# MSS_CTRL_MSS_CTRL_50D00000h register map
Vendor: Texas Instruments
Registers are 32-bit, read-write, reset values left out (the file's numbers can be read two ways) unless marked. A register's access mark holds for its fields unless they carry their own. Offsets are as the file gives them; [hi:lo] are bit positions; {n}, {i} and the like mark numbered series.

## MSS_CTRL (part 3 of 4)
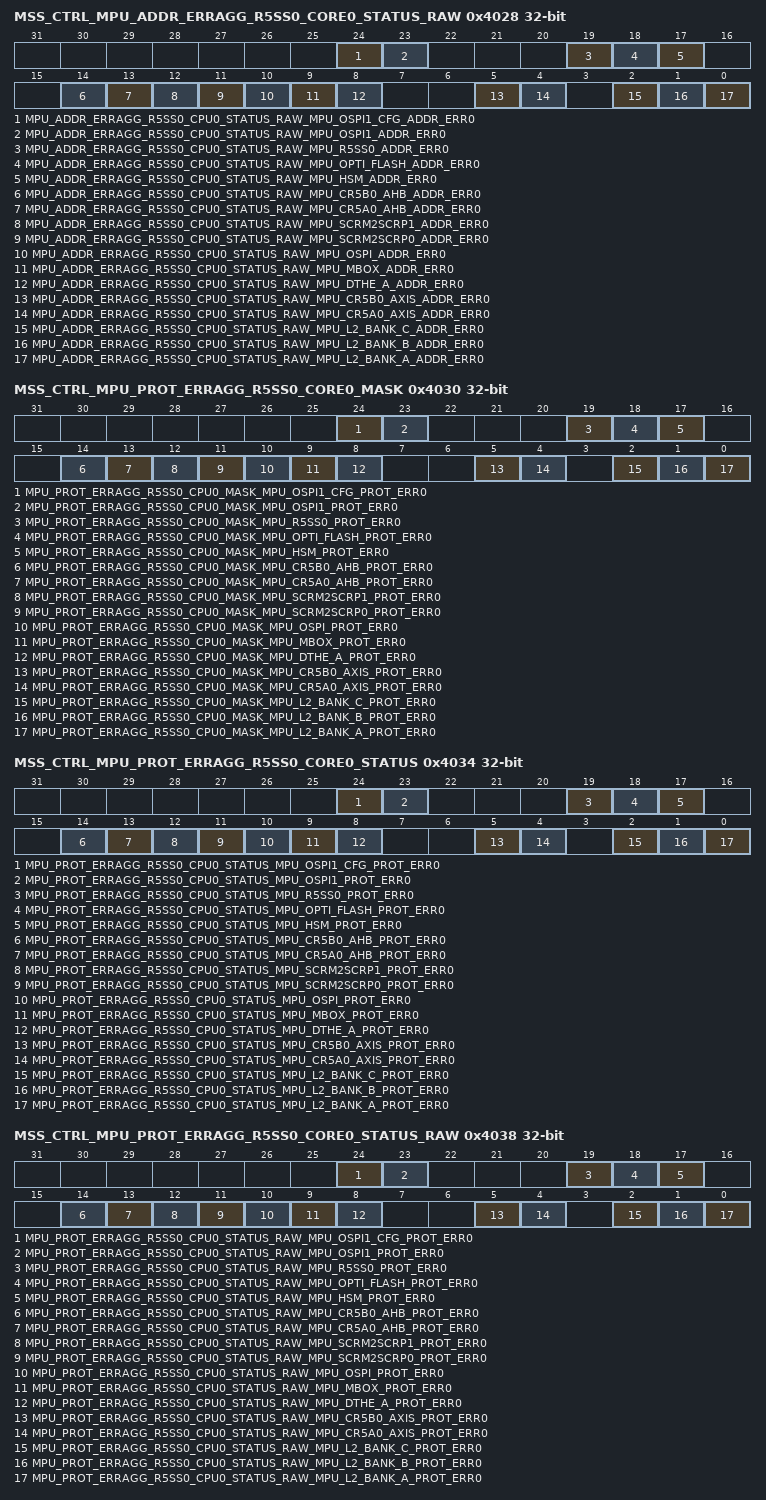
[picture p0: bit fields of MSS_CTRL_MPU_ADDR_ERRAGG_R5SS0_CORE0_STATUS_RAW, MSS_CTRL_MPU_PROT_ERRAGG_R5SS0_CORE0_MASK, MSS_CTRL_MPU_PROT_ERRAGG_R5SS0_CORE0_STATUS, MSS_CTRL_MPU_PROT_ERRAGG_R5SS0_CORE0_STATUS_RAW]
0x4028 MSS_CTRL_MPU_ADDR_ERRAGG_R5SS0_CORE0_STATUS_RAW access not given — This register shows the Status of all MPU Address Errors.
  [24] MPU_ADDR_ERRAGG_R5SS0_CPU0_STATUS_RAW_MPU_OSPI1_CFG_ADDR_ERR0 — Raw Status of Error from MPU_ADDR_INTR. Set irrespective if the Interupt is masked or unmasked in MPU_ADDR_INTR_ERRAGG_MASK (access R/W1TC)
  [23] MPU_ADDR_ERRAGG_R5SS0_CPU0_STATUS_RAW_MPU_OSPI1_ADDR_ERR0 — Raw Status of Error from MPU_ADDR_INTR. Set irrespective if the Interupt is masked or unmasked in MPU_ADDR_INTR_ERRAGG_MASK (access R/W1TC)
  [19] MPU_ADDR_ERRAGG_R5SS0_CPU0_STATUS_RAW_MPU_R5SS0_ADDR_ERR0 — Raw Status of Error from MPU_ADDR_INTR. Set irrespective if the Interupt is masked or unmasked in MPU_ADDR_INTR_ERRAGG_MASK (access R/W1TC)
  [18] MPU_ADDR_ERRAGG_R5SS0_CPU0_STATUS_RAW_MPU_OPTI_FLASH_ADDR_ERR0 — Raw Status of Error from MPU_ADDR_INTR. Set irrespective if the Interupt is masked or unmasked in MPU_ADDR_INTR_ERRAGG_MASK (access R/W1TC)
  [17] MPU_ADDR_ERRAGG_R5SS0_CPU0_STATUS_RAW_MPU_HSM_ADDR_ERR0 — Raw Status of Error from MPU_ADDR_INTR. Set irrespective if the Interupt is masked or unmasked in MPU_ADDR_INTR_ERRAGG_MASK (access R/W1TC)
  [14] MPU_ADDR_ERRAGG_R5SS0_CPU0_STATUS_RAW_MPU_CR5B0_AHB_ADDR_ERR0 — Raw Status of Error from MPU_ADDR_INTR. Set irrespective if the Interupt is masked or unmasked in MPU_ADDR_INTR_ERRAGG_MASK (access R/W1TC)
  [13] MPU_ADDR_ERRAGG_R5SS0_CPU0_STATUS_RAW_MPU_CR5A0_AHB_ADDR_ERR0 — Raw Status of Error from MPU_ADDR_INTR. Set irrespective if the Interupt is masked or unmasked in MPU_ADDR_INTR_ERRAGG_MASK (access R/W1TC)
  [12] MPU_ADDR_ERRAGG_R5SS0_CPU0_STATUS_RAW_MPU_SCRM2SCRP1_ADDR_ERR0 — Raw Status of Error from MPU_ADDR_INTR. Set irrespective if the Interupt is masked or unmasked in MPU_ADDR_INTR_ERRAGG_MASK (access R/W1TC)
  [11] MPU_ADDR_ERRAGG_R5SS0_CPU0_STATUS_RAW_MPU_SCRM2SCRP0_ADDR_ERR0 — Raw Status of Error from MPU_ADDR_INTR. Set irrespective if the Interupt is masked or unmasked in MPU_ADDR_INTR_ERRAGG_MASK (access R/W1TC)
  [10] MPU_ADDR_ERRAGG_R5SS0_CPU0_STATUS_RAW_MPU_OSPI_ADDR_ERR0 — Raw Status of Error from MPU_ADDR_INTR. Set irrespective if the Interupt is masked or unmasked in MPU_ADDR_INTR_ERRAGG_MASK (access R/W1TC)
  [9] MPU_ADDR_ERRAGG_R5SS0_CPU0_STATUS_RAW_MPU_MBOX_ADDR_ERR0 — Raw Status of Error from MPU_ADDR_INTR. Set irrespective if the Interupt is masked or unmasked in MPU_ADDR_INTR_ERRAGG_MASK (access R/W1TC)
  [8] MPU_ADDR_ERRAGG_R5SS0_CPU0_STATUS_RAW_MPU_DTHE_A_ADDR_ERR0 — Raw Status of Error from MPU_ADDR_INTR. Set irrespective if the Interupt is masked or unmasked in MPU_ADDR_INTR_ERRAGG_MASK (access R/W1TC)
  [5] MPU_ADDR_ERRAGG_R5SS0_CPU0_STATUS_RAW_MPU_CR5B0_AXIS_ADDR_ERR0 — Raw Status of Error from MPU_ADDR_INTR. Set irrespective if the Interupt is masked or unmasked in MPU_ADDR_INTR_ERRAGG_MASK (access R/W1TC)
  [4] MPU_ADDR_ERRAGG_R5SS0_CPU0_STATUS_RAW_MPU_CR5A0_AXIS_ADDR_ERR0 — Raw Status of Error from MPU_ADDR_INTR. Set irrespective if the Interupt is masked or unmasked in MPU_ADDR_INTR_ERRAGG_MASK (access R/W1TC)
  [2] MPU_ADDR_ERRAGG_R5SS0_CPU0_STATUS_RAW_MPU_L2_BANK_C_ADDR_ERR0 — Raw Status of Error from MPU_ADDR_INTR. Set irrespective if the Interupt is masked or unmasked in MPU_ADDR_INTR_ERRAGG_MASK (access R/W1TC)
  [1] MPU_ADDR_ERRAGG_R5SS0_CPU0_STATUS_RAW_MPU_L2_BANK_B_ADDR_ERR0 — Raw Status of Error from MPU_ADDR_INTR. Set irrespective if the Interupt is masked or unmasked in MPU_ADDR_INTR_ERRAGG_MASK (access R/W1TC)
  [0] MPU_ADDR_ERRAGG_R5SS0_CPU0_STATUS_RAW_MPU_L2_BANK_A_ADDR_ERR0 — Raw Status of Error from MPU_ADDR_INTR. Set irrespective if the Interupt is masked or unmasked in MPU_ADDR_INTR_ERRAGG_MASK (access R/W1TC)
0x4030 MSS_CTRL_MPU_PROT_ERRAGG_R5SS0_CORE0_MASK — This register Masks selected interrupt soures from generating MPU Protection Error Interrupt to R5SS0 CORE0 .
  [24] MPU_PROT_ERRAGG_R5SS0_CPU0_MASK_MPU_OSPI1_CFG_PROT_ERR0 — Mask Error from MPU_PROT_INTR to aggregated Error MPU_PROT_INTR_ERRAGG1 : Error is Masked0 : Error is Unmasked
  [23] MPU_PROT_ERRAGG_R5SS0_CPU0_MASK_MPU_OSPI1_PROT_ERR0 — Mask Error from MPU_PROT_INTR to aggregated Error MPU_PROT_INTR_ERRAGG1 : Error is Masked0 : Error is Unmasked
  [19] MPU_PROT_ERRAGG_R5SS0_CPU0_MASK_MPU_R5SS0_PROT_ERR0 — Mask Error from MPU_PROT_INTR to aggregated Error MPU_PROT_INTR_ERRAGG1 : Error is Masked0 : Error is Unmasked
  [18] MPU_PROT_ERRAGG_R5SS0_CPU0_MASK_MPU_OPTI_FLASH_PROT_ERR0 — Mask Error from MPU_PROT_INTR to aggregated Error MPU_PROT_INTR_ERRAGG1 : Error is Masked0 : Error is Unmasked
  [17] MPU_PROT_ERRAGG_R5SS0_CPU0_MASK_MPU_HSM_PROT_ERR0 — Mask Error from MPU_PROT_INTR to aggregated Error MPU_PROT_INTR_ERRAGG1 : Error is Masked0 : Error is Unmasked
  [14] MPU_PROT_ERRAGG_R5SS0_CPU0_MASK_MPU_CR5B0_AHB_PROT_ERR0 — Mask Error from MPU_PROT_INTR to aggregated Error MPU_PROT_INTR_ERRAGG1 : Error is Masked0 : Error is Unmasked
  [13] MPU_PROT_ERRAGG_R5SS0_CPU0_MASK_MPU_CR5A0_AHB_PROT_ERR0 — Mask Error from MPU_PROT_INTR to aggregated Error MPU_PROT_INTR_ERRAGG1 : Error is Masked0 : Error is Unmasked
  [12] MPU_PROT_ERRAGG_R5SS0_CPU0_MASK_MPU_SCRM2SCRP1_PROT_ERR0 — Mask Error from MPU_PROT_INTR to aggregated Error MPU_PROT_INTR_ERRAGG1 : Error is Masked0 : Error is Unmasked
  [11] MPU_PROT_ERRAGG_R5SS0_CPU0_MASK_MPU_SCRM2SCRP0_PROT_ERR0 — Mask Error from MPU_PROT_INTR to aggregated Error MPU_PROT_INTR_ERRAGG1 : Error is Masked0 : Error is Unmasked
  [10] MPU_PROT_ERRAGG_R5SS0_CPU0_MASK_MPU_OSPI_PROT_ERR0 — Mask Error from MPU_PROT_INTR to aggregated Error MPU_PROT_INTR_ERRAGG1 : Error is Masked0 : Error is Unmasked
  [9] MPU_PROT_ERRAGG_R5SS0_CPU0_MASK_MPU_MBOX_PROT_ERR0 — Mask Error from MPU_PROT_INTR to aggregated Error MPU_PROT_INTR_ERRAGG1 : Error is Masked0 : Error is Unmasked
  [8] MPU_PROT_ERRAGG_R5SS0_CPU0_MASK_MPU_DTHE_A_PROT_ERR0 — Mask Error from MPU_PROT_INTR to aggregated Error MPU_PROT_INTR_ERRAGG1 : Error is Masked0 : Error is Unmasked
  [5] MPU_PROT_ERRAGG_R5SS0_CPU0_MASK_MPU_CR5B0_AXIS_PROT_ERR0 — Mask Error from MPU_PROT_INTR to aggregated Error MPU_PROT_INTR_ERRAGG1 : Error is Masked0 : Error is Unmasked
  [4] MPU_PROT_ERRAGG_R5SS0_CPU0_MASK_MPU_CR5A0_AXIS_PROT_ERR0 — Mask Error from MPU_PROT_INTR to aggregated Error MPU_PROT_INTR_ERRAGG1 : Error is Masked0 : Error is Unmasked
  [2] MPU_PROT_ERRAGG_R5SS0_CPU0_MASK_MPU_L2_BANK_C_PROT_ERR0 — Mask Error from MPU_PROT_INTR to aggregated Error MPU_PROT_INTR_ERRAGG1 : Error is Masked0 : Error is Unmasked
  [1] MPU_PROT_ERRAGG_R5SS0_CPU0_MASK_MPU_L2_BANK_B_PROT_ERR0 — Mask Error from MPU_PROT_INTR to aggregated Error MPU_PROT_INTR_ERRAGG1 : Error is Masked0 : Error is Unmasked
  [0] MPU_PROT_ERRAGG_R5SS0_CPU0_MASK_MPU_L2_BANK_A_PROT_ERR0 — Mask Error from MPU_PROT_INTR to aggregated Error MPU_PROT_INTR_ERRAGG1 : Error is Masked0 : Error is Unmasked
0x4034 MSS_CTRL_MPU_PROT_ERRAGG_R5SS0_CORE0_STATUS access not given — This register shows the Status of Unmasked MPU Protection Errors to R5SS0 Core0 .
  [24] MPU_PROT_ERRAGG_R5SS0_CPU0_STATUS_MPU_OSPI1_CFG_PROT_ERR0 — Status of Error from MPU_PROT_INTR. Set only if Interupt is unmasked in MPU_PROT_INTR_ERRAGG_MASKWrie 0x1 to clear this Error. (access R/W1TC)
  [23] MPU_PROT_ERRAGG_R5SS0_CPU0_STATUS_MPU_OSPI1_PROT_ERR0 — Status of Error from MPU_PROT_INTR. Set only if Interupt is unmasked in MPU_PROT_INTR_ERRAGG_MASKWrie 0x1 to clear this Error. (access R/W1TC)
  [19] MPU_PROT_ERRAGG_R5SS0_CPU0_STATUS_MPU_R5SS0_PROT_ERR0 — Status of Error from MPU_PROT_INTR. Set only if Interupt is unmasked in MPU_PROT_INTR_ERRAGG_MASKWrie 0x1 to clear this Error. (access R/W1TC)
  [18] MPU_PROT_ERRAGG_R5SS0_CPU0_STATUS_MPU_OPTI_FLASH_PROT_ERR0 — Status of Error from MPU_PROT_INTR. Set only if Interupt is unmasked in MPU_PROT_INTR_ERRAGG_MASKWrie 0x1 to clear this Error. (access R/W1TC)
  [17] MPU_PROT_ERRAGG_R5SS0_CPU0_STATUS_MPU_HSM_PROT_ERR0 — Status of Error from MPU_PROT_INTR. Set only if Interupt is unmasked in MPU_PROT_INTR_ERRAGG_MASKWrie 0x1 to clear this Error. (access R/W1TC)
  [14] MPU_PROT_ERRAGG_R5SS0_CPU0_STATUS_MPU_CR5B0_AHB_PROT_ERR0 — Status of Error from MPU_PROT_INTR. Set only if Interupt is unmasked in MPU_PROT_INTR_ERRAGG_MASKWrie 0x1 to clear this Error. (access R/W1TC)
  [13] MPU_PROT_ERRAGG_R5SS0_CPU0_STATUS_MPU_CR5A0_AHB_PROT_ERR0 — Status of Error from MPU_PROT_INTR. Set only if Interupt is unmasked in MPU_PROT_INTR_ERRAGG_MASKWrie 0x1 to clear this Error. (access R/W1TC)
  [12] MPU_PROT_ERRAGG_R5SS0_CPU0_STATUS_MPU_SCRM2SCRP1_PROT_ERR0 — Status of Error from MPU_PROT_INTR. Set only if Interupt is unmasked in MPU_PROT_INTR_ERRAGG_MASKWrie 0x1 to clear this Error. (access R/W1TC)
  [11] MPU_PROT_ERRAGG_R5SS0_CPU0_STATUS_MPU_SCRM2SCRP0_PROT_ERR0 — Status of Error from MPU_PROT_INTR. Set only if Interupt is unmasked in MPU_PROT_INTR_ERRAGG_MASKWrie 0x1 to clear this Error. (access R/W1TC)
  [10] MPU_PROT_ERRAGG_R5SS0_CPU0_STATUS_MPU_OSPI_PROT_ERR0 — Status of Error from MPU_PROT_INTR. Set only if Interupt is unmasked in MPU_PROT_INTR_ERRAGG_MASKWrie 0x1 to clear this Error. (access R/W1TC)
  [9] MPU_PROT_ERRAGG_R5SS0_CPU0_STATUS_MPU_MBOX_PROT_ERR0 — Status of Error from MPU_PROT_INTR. Set only if Interupt is unmasked in MPU_PROT_INTR_ERRAGG_MASKWrie 0x1 to clear this Error. (access R/W1TC)
  [8] MPU_PROT_ERRAGG_R5SS0_CPU0_STATUS_MPU_DTHE_A_PROT_ERR0 — Status of Error from MPU_PROT_INTR. Set only if Interupt is unmasked in MPU_PROT_INTR_ERRAGG_MASKWrie 0x1 to clear this Error. (access R/W1TC)
  [5] MPU_PROT_ERRAGG_R5SS0_CPU0_STATUS_MPU_CR5B0_AXIS_PROT_ERR0 — Status of Error from MPU_PROT_INTR. Set only if Interupt is unmasked in MPU_PROT_INTR_ERRAGG_MASKWrie 0x1 to clear this Error. (access R/W1TC)
  [4] MPU_PROT_ERRAGG_R5SS0_CPU0_STATUS_MPU_CR5A0_AXIS_PROT_ERR0 — Status of Error from MPU_PROT_INTR. Set only if Interupt is unmasked in MPU_PROT_INTR_ERRAGG_MASKWrie 0x1 to clear this Error. (access R/W1TC)
  [2] MPU_PROT_ERRAGG_R5SS0_CPU0_STATUS_MPU_L2_BANK_C_PROT_ERR0 — Status of Error from MPU_PROT_INTR. Set only if Interupt is unmasked in MPU_PROT_INTR_ERRAGG_MASKWrie 0x1 to clear this Error. (access R/W1TC)
  [1] MPU_PROT_ERRAGG_R5SS0_CPU0_STATUS_MPU_L2_BANK_B_PROT_ERR0 — Status of Error from MPU_PROT_INTR. Set only if Interupt is unmasked in MPU_PROT_INTR_ERRAGG_MASKWrie 0x1 to clear this Error. (access R/W1TC)
  [0] MPU_PROT_ERRAGG_R5SS0_CPU0_STATUS_MPU_L2_BANK_A_PROT_ERR0 — Status of Error from MPU_PROT_INTR. Set only if Interupt is unmasked in MPU_PROT_INTR_ERRAGG_MASKWrie 0x1 to clear this Error. (access R/W1TC)
0x4038 MSS_CTRL_MPU_PROT_ERRAGG_R5SS0_CORE0_STATUS_RAW access not given — This register shows the Status of all MPU Protection Errors.
  [24] MPU_PROT_ERRAGG_R5SS0_CPU0_STATUS_RAW_MPU_OSPI1_CFG_PROT_ERR0 — Raw Status of Error from MPU_PROT_INTR. Set irrespective if the Interupt is masked or unmasked in MPU_PROT_INTR_ERRAGG_MASK (access R/W1TC)
  [23] MPU_PROT_ERRAGG_R5SS0_CPU0_STATUS_RAW_MPU_OSPI1_PROT_ERR0 — Raw Status of Error from MPU_PROT_INTR. Set irrespective if the Interupt is masked or unmasked in MPU_PROT_INTR_ERRAGG_MASK (access R/W1TC)
  [19] MPU_PROT_ERRAGG_R5SS0_CPU0_STATUS_RAW_MPU_R5SS0_PROT_ERR0 — Raw Status of Error from MPU_PROT_INTR. Set irrespective if the Interupt is masked or unmasked in MPU_PROT_INTR_ERRAGG_MASK (access R/W1TC)
  [18] MPU_PROT_ERRAGG_R5SS0_CPU0_STATUS_RAW_MPU_OPTI_FLASH_PROT_ERR0 — Raw Status of Error from MPU_PROT_INTR. Set irrespective if the Interupt is masked or unmasked in MPU_PROT_INTR_ERRAGG_MASK (access R/W1TC)
  [17] MPU_PROT_ERRAGG_R5SS0_CPU0_STATUS_RAW_MPU_HSM_PROT_ERR0 — Raw Status of Error from MPU_PROT_INTR. Set irrespective if the Interupt is masked or unmasked in MPU_PROT_INTR_ERRAGG_MASK (access R/W1TC)
  [14] MPU_PROT_ERRAGG_R5SS0_CPU0_STATUS_RAW_MPU_CR5B0_AHB_PROT_ERR0 — Raw Status of Error from MPU_PROT_INTR. Set irrespective if the Interupt is masked or unmasked in MPU_PROT_INTR_ERRAGG_MASK (access R/W1TC)
  [13] MPU_PROT_ERRAGG_R5SS0_CPU0_STATUS_RAW_MPU_CR5A0_AHB_PROT_ERR0 — Raw Status of Error from MPU_PROT_INTR. Set irrespective if the Interupt is masked or unmasked in MPU_PROT_INTR_ERRAGG_MASK (access R/W1TC)
  [12] MPU_PROT_ERRAGG_R5SS0_CPU0_STATUS_RAW_MPU_SCRM2SCRP1_PROT_ERR0 — Raw Status of Error from MPU_PROT_INTR. Set irrespective if the Interupt is masked or unmasked in MPU_PROT_INTR_ERRAGG_MASK (access R/W1TC)
  [11] MPU_PROT_ERRAGG_R5SS0_CPU0_STATUS_RAW_MPU_SCRM2SCRP0_PROT_ERR0 — Raw Status of Error from MPU_PROT_INTR. Set irrespective if the Interupt is masked or unmasked in MPU_PROT_INTR_ERRAGG_MASK (access R/W1TC)
  [10] MPU_PROT_ERRAGG_R5SS0_CPU0_STATUS_RAW_MPU_OSPI_PROT_ERR0 — Raw Status of Error from MPU_PROT_INTR. Set irrespective if the Interupt is masked or unmasked in MPU_PROT_INTR_ERRAGG_MASK (access R/W1TC)
  [9] MPU_PROT_ERRAGG_R5SS0_CPU0_STATUS_RAW_MPU_MBOX_PROT_ERR0 — Raw Status of Error from MPU_PROT_INTR. Set irrespective if the Interupt is masked or unmasked in MPU_PROT_INTR_ERRAGG_MASK (access R/W1TC)
  [8] MPU_PROT_ERRAGG_R5SS0_CPU0_STATUS_RAW_MPU_DTHE_A_PROT_ERR0 — Raw Status of Error from MPU_PROT_INTR. Set irrespective if the Interupt is masked or unmasked in MPU_PROT_INTR_ERRAGG_MASK (access R/W1TC)
  [5] MPU_PROT_ERRAGG_R5SS0_CPU0_STATUS_RAW_MPU_CR5B0_AXIS_PROT_ERR0 — Raw Status of Error from MPU_PROT_INTR. Set irrespective if the Interupt is masked or unmasked in MPU_PROT_INTR_ERRAGG_MASK (access R/W1TC)
  [4] MPU_PROT_ERRAGG_R5SS0_CPU0_STATUS_RAW_MPU_CR5A0_AXIS_PROT_ERR0 — Raw Status of Error from MPU_PROT_INTR. Set irrespective if the Interupt is masked or unmasked in MPU_PROT_INTR_ERRAGG_MASK (access R/W1TC)
  [2] MPU_PROT_ERRAGG_R5SS0_CPU0_STATUS_RAW_MPU_L2_BANK_C_PROT_ERR0 — Raw Status of Error from MPU_PROT_INTR. Set irrespective if the Interupt is masked or unmasked in MPU_PROT_INTR_ERRAGG_MASK (access R/W1TC)
  [1] MPU_PROT_ERRAGG_R5SS0_CPU0_STATUS_RAW_MPU_L2_BANK_B_PROT_ERR0 — Raw Status of Error from MPU_PROT_INTR. Set irrespective if the Interupt is masked or unmasked in MPU_PROT_INTR_ERRAGG_MASK (access R/W1TC)
  [0] MPU_PROT_ERRAGG_R5SS0_CPU0_STATUS_RAW_MPU_L2_BANK_A_PROT_ERR0 — Raw Status of Error from MPU_PROT_INTR. Set irrespective if the Interupt is masked or unmasked in MPU_PROT_INTR_ERRAGG_MASK (access R/W1TC)
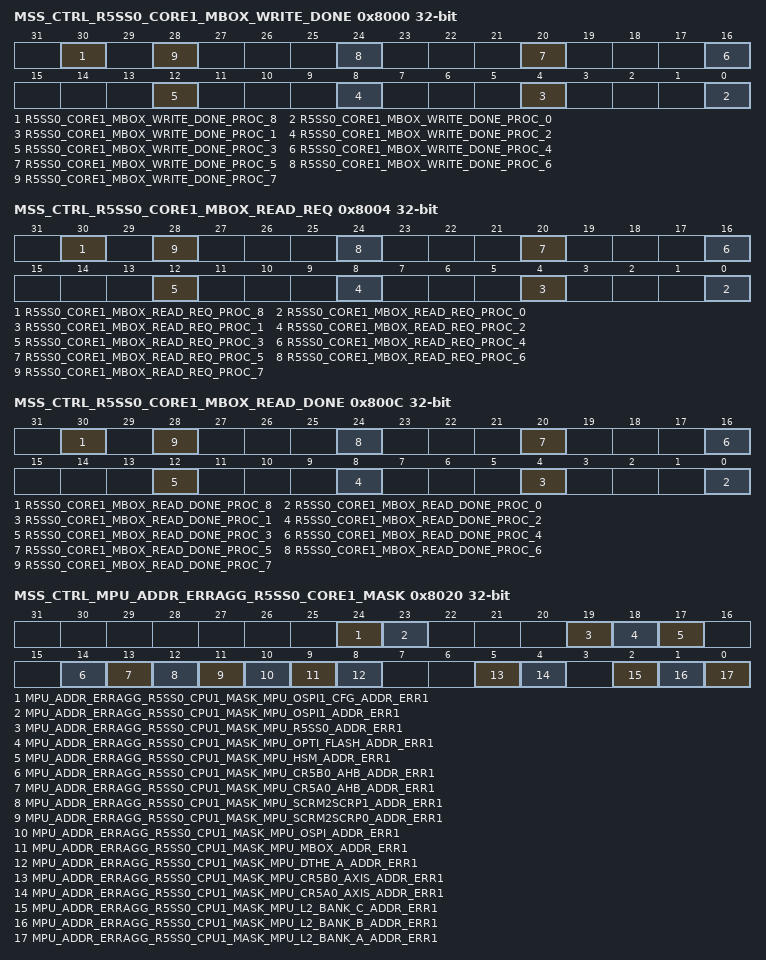
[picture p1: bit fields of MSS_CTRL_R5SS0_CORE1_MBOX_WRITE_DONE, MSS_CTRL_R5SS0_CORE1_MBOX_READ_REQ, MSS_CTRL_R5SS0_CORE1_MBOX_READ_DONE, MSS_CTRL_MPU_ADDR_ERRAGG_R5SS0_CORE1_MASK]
0x8000 MSS_CTRL_R5SS0_CORE1_MBOX_WRITE_DONE — This register is used by R5SS0 Core 1 to generate Mailbox interrupt to Recipent CPU.
  [30] R5SS0_CORE1_MBOX_WRITE_DONE_PROC_8 — Write pulse bit field:This register should be written once finishing Writing into the mailbox memory of processor 8
  [4n] R5SS0_CORE1_MBOX_WRITE_DONE_PROC_{n} (n=0..7) — Write pulse bit field:This register should be written once finishing Writing into the mailbox memory of processor {n}
0x8004 MSS_CTRL_R5SS0_CORE1_MBOX_READ_REQ access not given — This register is used by R5SS0 Core 1 to know the Sender of Mailbox Interrupt as well as clear it.
  [30] R5SS0_CORE1_MBOX_READ_REQ_PROC_8 — This is request from processor 8 to mss_CR5B. Requesting it to read from mailbox. (access R/W1TC)
  [4n] R5SS0_CORE1_MBOX_READ_REQ_PROC_{n} (n=0..7) — This is request from processor {n} to mss_CR5B. Requesting it to read from mailbox. (access R/W1TC)
0x8008 MSS_CTRL_R5SS0_CORE1_MBOX_READ_DONE_ACK — This register is used by R5SS0 Core 1 to generate Mailbox Read acknowledgement to the Sender CPU.
  [8:0] R5SS0_CORE1_MBOX_READ_DONE_ACK_PROC — Write pulse bit field:For bits 0 to7:Wrting1'b1 : Generates pulse interrupt to corresponding proc from MSS_CR5
0x800C MSS_CTRL_R5SS0_CORE1_MBOX_READ_DONE access not given — This register is used by R5SS0 Core 1 to know that the Receiver CPU has read the Mailbox and Acked. It is also used to clear the Read Done Interrupt.
  [30] R5SS0_CORE1_MBOX_READ_DONE_PROC_8 — This register should be written once finishing Reading from CR5B's mailbox written by proc 8 (access R/W1TC)
  [4n] R5SS0_CORE1_MBOX_READ_DONE_PROC_{n} (n=0..7) — This register should be written once finishing Reading from CR5B's mailbox written by proc {n} (access R/W1TC)
0x8010 MSS_CTRL_R5SS0_CORE1_SW_INT — This Register is used to generate a S/W Triggered Interrupt to R5SS0 Core1.
  [0] R5SS0_CORE1_SW_INT_PULSE — Write_pulse bit field:Writing 1'b1 to each bit will trigger MSS_SW_INT respectively to CR5A/B.
0x8020 MSS_CTRL_MPU_ADDR_ERRAGG_R5SS0_CORE1_MASK — This register Masks selected interrupt soures from generating MPU Address Error Interrupt to R5SS0 CORE1 .
  [24] MPU_ADDR_ERRAGG_R5SS0_CPU1_MASK_MPU_OSPI1_CFG_ADDR_ERR1 — Mask Error from MPU_ADDR_INTR to aggregated Error MPU_ADDR_INTR_ERRAGG1 : Error is Masked0 : Error is Unmasked
  [23] MPU_ADDR_ERRAGG_R5SS0_CPU1_MASK_MPU_OSPI1_ADDR_ERR1 — Mask Error from MPU_ADDR_INTR to aggregated Error MPU_ADDR_INTR_ERRAGG1 : Error is Masked0 : Error is Unmasked
  [19] MPU_ADDR_ERRAGG_R5SS0_CPU1_MASK_MPU_R5SS0_ADDR_ERR1 — Mask Error from MPU_ADDR_INTR to aggregated Error MPU_ADDR_INTR_ERRAGG1 : Error is Masked0 : Error is Unmasked
  [18] MPU_ADDR_ERRAGG_R5SS0_CPU1_MASK_MPU_OPTI_FLASH_ADDR_ERR1 — Mask Error from MPU_ADDR_INTR to aggregated Error MPU_ADDR_INTR_ERRAGG1 : Error is Masked0 : Error is Unmasked
  [17] MPU_ADDR_ERRAGG_R5SS0_CPU1_MASK_MPU_HSM_ADDR_ERR1 — Mask Error from MPU_ADDR_INTR to aggregated Error MPU_ADDR_INTR_ERRAGG1 : Error is Masked0 : Error is Unmasked
  [14] MPU_ADDR_ERRAGG_R5SS0_CPU1_MASK_MPU_CR5B0_AHB_ADDR_ERR1 — Mask Error from MPU_ADDR_INTR to aggregated Error MPU_ADDR_INTR_ERRAGG1 : Error is Masked0 : Error is Unmasked
  [13] MPU_ADDR_ERRAGG_R5SS0_CPU1_MASK_MPU_CR5A0_AHB_ADDR_ERR1 — Mask Error from MPU_ADDR_INTR to aggregated Error MPU_ADDR_INTR_ERRAGG1 : Error is Masked0 : Error is Unmasked
  [12] MPU_ADDR_ERRAGG_R5SS0_CPU1_MASK_MPU_SCRM2SCRP1_ADDR_ERR1 — Mask Error from MPU_ADDR_INTR to aggregated Error MPU_ADDR_INTR_ERRAGG1 : Error is Masked0 : Error is Unmasked
  [11] MPU_ADDR_ERRAGG_R5SS0_CPU1_MASK_MPU_SCRM2SCRP0_ADDR_ERR1 — Mask Error from MPU_ADDR_INTR to aggregated Error MPU_ADDR_INTR_ERRAGG1 : Error is Masked0 : Error is Unmasked
  [10] MPU_ADDR_ERRAGG_R5SS0_CPU1_MASK_MPU_OSPI_ADDR_ERR1 — Mask Error from MPU_ADDR_INTR to aggregated Error MPU_ADDR_INTR_ERRAGG1 : Error is Masked0 : Error is Unmasked
  [9] MPU_ADDR_ERRAGG_R5SS0_CPU1_MASK_MPU_MBOX_ADDR_ERR1 — Mask Error from MPU_ADDR_INTR to aggregated Error MPU_ADDR_INTR_ERRAGG1 : Error is Masked0 : Error is Unmasked
  [8] MPU_ADDR_ERRAGG_R5SS0_CPU1_MASK_MPU_DTHE_A_ADDR_ERR1 — Mask Error from MPU_ADDR_INTR to aggregated Error MPU_ADDR_INTR_ERRAGG1 : Error is Masked0 : Error is Unmasked
  [5] MPU_ADDR_ERRAGG_R5SS0_CPU1_MASK_MPU_CR5B0_AXIS_ADDR_ERR1 — Mask Error from MPU_ADDR_INTR to aggregated Error MPU_ADDR_INTR_ERRAGG1 : Error is Masked0 : Error is Unmasked
  [4] MPU_ADDR_ERRAGG_R5SS0_CPU1_MASK_MPU_CR5A0_AXIS_ADDR_ERR1 — Mask Error from MPU_ADDR_INTR to aggregated Error MPU_ADDR_INTR_ERRAGG1 : Error is Masked0 : Error is Unmasked
  [2] MPU_ADDR_ERRAGG_R5SS0_CPU1_MASK_MPU_L2_BANK_C_ADDR_ERR1 — Mask Error from MPU_ADDR_INTR to aggregated Error MPU_ADDR_INTR_ERRAGG1 : Error is Masked0 : Error is Unmasked
  [1] MPU_ADDR_ERRAGG_R5SS0_CPU1_MASK_MPU_L2_BANK_B_ADDR_ERR1 — Mask Error from MPU_ADDR_INTR to aggregated Error MPU_ADDR_INTR_ERRAGG1 : Error is Masked0 : Error is Unmasked
  [0] MPU_ADDR_ERRAGG_R5SS0_CPU1_MASK_MPU_L2_BANK_A_ADDR_ERR1 — Mask Error from MPU_ADDR_INTR to aggregated Error MPU_ADDR_INTR_ERRAGG1 : Error is Masked0 : Error is Unmasked
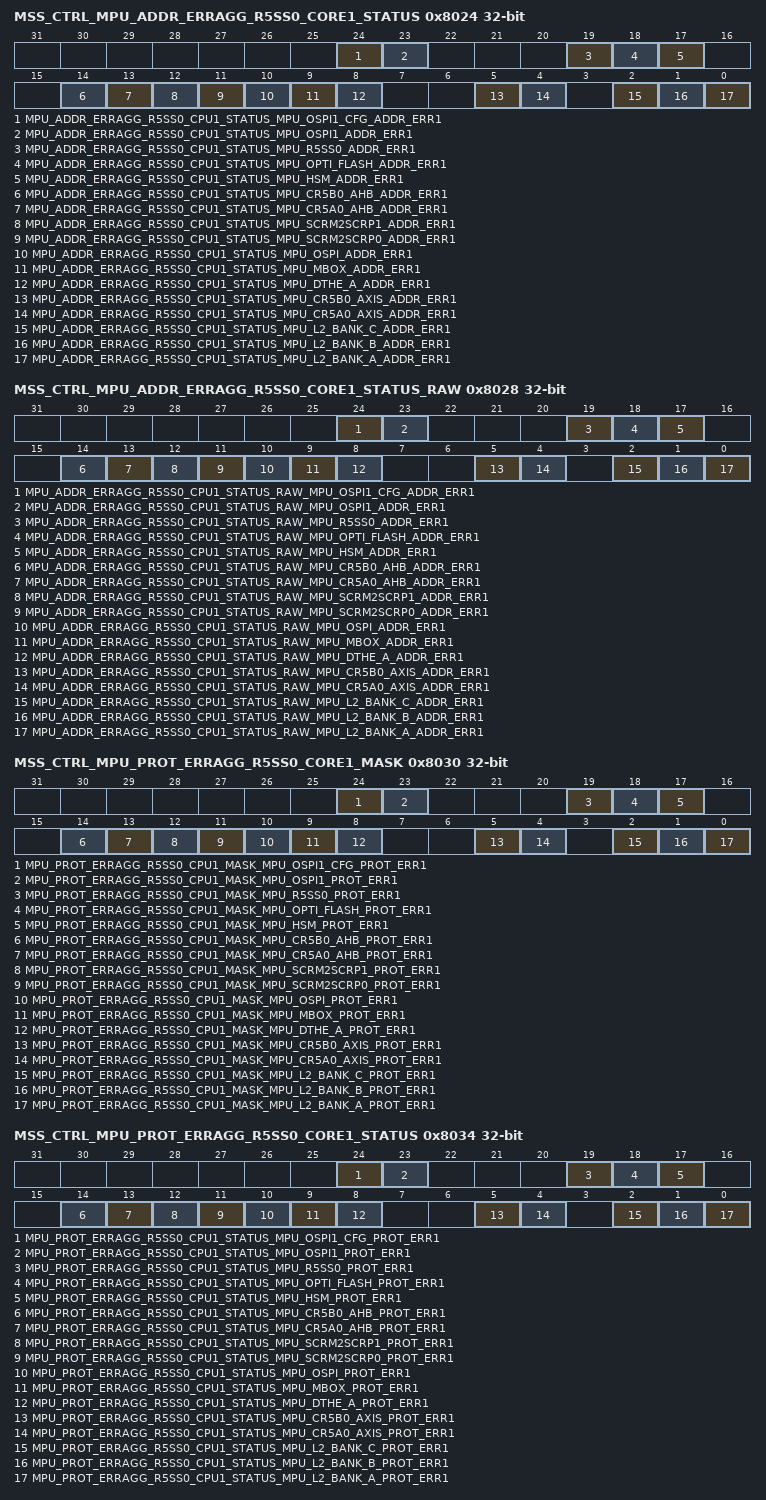
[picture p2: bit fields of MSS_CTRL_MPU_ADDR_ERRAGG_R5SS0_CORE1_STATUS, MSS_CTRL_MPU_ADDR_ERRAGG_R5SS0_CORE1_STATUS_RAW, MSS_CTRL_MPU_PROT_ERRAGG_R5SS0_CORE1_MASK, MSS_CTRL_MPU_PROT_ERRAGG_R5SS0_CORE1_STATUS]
0x8024 MSS_CTRL_MPU_ADDR_ERRAGG_R5SS0_CORE1_STATUS access not given — This register shows the Status of Unmasked MPU Address Errors to R5SS0 CORE1 .
  [24] MPU_ADDR_ERRAGG_R5SS0_CPU1_STATUS_MPU_OSPI1_CFG_ADDR_ERR1 — Status of Error from MPU_ADDR_INTR. Set only if Interupt is unmasked in MPU_ADDR_INTR_ERRAGG_MASKWrie 0x1 to clear this Error. (access R/W1TC)
  [23] MPU_ADDR_ERRAGG_R5SS0_CPU1_STATUS_MPU_OSPI1_ADDR_ERR1 — Status of Error from MPU_ADDR_INTR. Set only if Interupt is unmasked in MPU_ADDR_INTR_ERRAGG_MASKWrie 0x1 to clear this Error. (access R/W1TC)
  [19] MPU_ADDR_ERRAGG_R5SS0_CPU1_STATUS_MPU_R5SS0_ADDR_ERR1 — Status of Error from MPU_ADDR_INTR. Set only if Interupt is unmasked in MPU_ADDR_INTR_ERRAGG_MASKWrie 0x1 to clear this Error. (access R/W1TC)
  [18] MPU_ADDR_ERRAGG_R5SS0_CPU1_STATUS_MPU_OPTI_FLASH_ADDR_ERR1 — Status of Error from MPU_ADDR_INTR. Set only if Interupt is unmasked in MPU_ADDR_INTR_ERRAGG_MASKWrie 0x1 to clear this Error. (access R/W1TC)
  [17] MPU_ADDR_ERRAGG_R5SS0_CPU1_STATUS_MPU_HSM_ADDR_ERR1 — Status of Error from MPU_ADDR_INTR. Set only if Interupt is unmasked in MPU_ADDR_INTR_ERRAGG_MASKWrie 0x1 to clear this Error. (access R/W1TC)
  [14] MPU_ADDR_ERRAGG_R5SS0_CPU1_STATUS_MPU_CR5B0_AHB_ADDR_ERR1 — Status of Error from MPU_ADDR_INTR. Set only if Interupt is unmasked in MPU_ADDR_INTR_ERRAGG_MASKWrie 0x1 to clear this Error. (access R/W1TC)
  [13] MPU_ADDR_ERRAGG_R5SS0_CPU1_STATUS_MPU_CR5A0_AHB_ADDR_ERR1 — Status of Error from MPU_ADDR_INTR. Set only if Interupt is unmasked in MPU_ADDR_INTR_ERRAGG_MASKWrie 0x1 to clear this Error. (access R/W1TC)
  [12] MPU_ADDR_ERRAGG_R5SS0_CPU1_STATUS_MPU_SCRM2SCRP1_ADDR_ERR1 — Status of Error from MPU_ADDR_INTR. Set only if Interupt is unmasked in MPU_ADDR_INTR_ERRAGG_MASKWrie 0x1 to clear this Error. (access R/W1TC)
  [11] MPU_ADDR_ERRAGG_R5SS0_CPU1_STATUS_MPU_SCRM2SCRP0_ADDR_ERR1 — Status of Error from MPU_ADDR_INTR. Set only if Interupt is unmasked in MPU_ADDR_INTR_ERRAGG_MASKWrie 0x1 to clear this Error. (access R/W1TC)
  [10] MPU_ADDR_ERRAGG_R5SS0_CPU1_STATUS_MPU_OSPI_ADDR_ERR1 — Status of Error from MPU_ADDR_INTR. Set only if Interupt is unmasked in MPU_ADDR_INTR_ERRAGG_MASKWrie 0x1 to clear this Error. (access R/W1TC)
  [9] MPU_ADDR_ERRAGG_R5SS0_CPU1_STATUS_MPU_MBOX_ADDR_ERR1 — Status of Error from MPU_ADDR_INTR. Set only if Interupt is unmasked in MPU_ADDR_INTR_ERRAGG_MASKWrie 0x1 to clear this Error. (access R/W1TC)
  [8] MPU_ADDR_ERRAGG_R5SS0_CPU1_STATUS_MPU_DTHE_A_ADDR_ERR1 — Status of Error from MPU_ADDR_INTR. Set only if Interupt is unmasked in MPU_ADDR_INTR_ERRAGG_MASKWrie 0x1 to clear this Error. (access R/W1TC)
  [5] MPU_ADDR_ERRAGG_R5SS0_CPU1_STATUS_MPU_CR5B0_AXIS_ADDR_ERR1 — Status of Error from MPU_ADDR_INTR. Set only if Interupt is unmasked in MPU_ADDR_INTR_ERRAGG_MASKWrie 0x1 to clear this Error. (access R/W1TC)
  [4] MPU_ADDR_ERRAGG_R5SS0_CPU1_STATUS_MPU_CR5A0_AXIS_ADDR_ERR1 — Status of Error from MPU_ADDR_INTR. Set only if Interupt is unmasked in MPU_ADDR_INTR_ERRAGG_MASKWrie 0x1 to clear this Error. (access R/W1TC)
  [2] MPU_ADDR_ERRAGG_R5SS0_CPU1_STATUS_MPU_L2_BANK_C_ADDR_ERR1 — Status of Error from MPU_ADDR_INTR. Set only if Interupt is unmasked in MPU_ADDR_INTR_ERRAGG_MASKWrie 0x1 to clear this Error. (access R/W1TC)
  [1] MPU_ADDR_ERRAGG_R5SS0_CPU1_STATUS_MPU_L2_BANK_B_ADDR_ERR1 — Status of Error from MPU_ADDR_INTR. Set only if Interupt is unmasked in MPU_ADDR_INTR_ERRAGG_MASKWrie 0x1 to clear this Error. (access R/W1TC)
  [0] MPU_ADDR_ERRAGG_R5SS0_CPU1_STATUS_MPU_L2_BANK_A_ADDR_ERR1 — Status of Error from MPU_ADDR_INTR. Set only if Interupt is unmasked in MPU_ADDR_INTR_ERRAGG_MASKWrie 0x1 to clear this Error. (access R/W1TC)
0x8028 MSS_CTRL_MPU_ADDR_ERRAGG_R5SS0_CORE1_STATUS_RAW access not given — This register shows the Status of all MPU Address Errors.
  [24] MPU_ADDR_ERRAGG_R5SS0_CPU1_STATUS_RAW_MPU_OSPI1_CFG_ADDR_ERR1 — Raw Status of Error from MPU_ADDR_INTR. Set irrespective if the Interupt is masked or unmasked in MPU_ADDR_INTR_ERRAGG_MASK (access R/W1TC)
  [23] MPU_ADDR_ERRAGG_R5SS0_CPU1_STATUS_RAW_MPU_OSPI1_ADDR_ERR1 — Raw Status of Error from MPU_ADDR_INTR. Set irrespective if the Interupt is masked or unmasked in MPU_ADDR_INTR_ERRAGG_MASK (access R/W1TC)
  [19] MPU_ADDR_ERRAGG_R5SS0_CPU1_STATUS_RAW_MPU_R5SS0_ADDR_ERR1 — Raw Status of Error from MPU_ADDR_INTR. Set irrespective if the Interupt is masked or unmasked in MPU_ADDR_INTR_ERRAGG_MASK (access R/W1TC)
  [18] MPU_ADDR_ERRAGG_R5SS0_CPU1_STATUS_RAW_MPU_OPTI_FLASH_ADDR_ERR1 — Raw Status of Error from MPU_ADDR_INTR. Set irrespective if the Interupt is masked or unmasked in MPU_ADDR_INTR_ERRAGG_MASK (access R/W1TC)
  [17] MPU_ADDR_ERRAGG_R5SS0_CPU1_STATUS_RAW_MPU_HSM_ADDR_ERR1 — Raw Status of Error from MPU_ADDR_INTR. Set irrespective if the Interupt is masked or unmasked in MPU_ADDR_INTR_ERRAGG_MASK (access R/W1TC)
  [14] MPU_ADDR_ERRAGG_R5SS0_CPU1_STATUS_RAW_MPU_CR5B0_AHB_ADDR_ERR1 — Raw Status of Error from MPU_ADDR_INTR. Set irrespective if the Interupt is masked or unmasked in MPU_ADDR_INTR_ERRAGG_MASK (access R/W1TC)
  [13] MPU_ADDR_ERRAGG_R5SS0_CPU1_STATUS_RAW_MPU_CR5A0_AHB_ADDR_ERR1 — Raw Status of Error from MPU_ADDR_INTR. Set irrespective if the Interupt is masked or unmasked in MPU_ADDR_INTR_ERRAGG_MASK (access R/W1TC)
  [12] MPU_ADDR_ERRAGG_R5SS0_CPU1_STATUS_RAW_MPU_SCRM2SCRP1_ADDR_ERR1 — Raw Status of Error from MPU_ADDR_INTR. Set irrespective if the Interupt is masked or unmasked in MPU_ADDR_INTR_ERRAGG_MASK (access R/W1TC)
  [11] MPU_ADDR_ERRAGG_R5SS0_CPU1_STATUS_RAW_MPU_SCRM2SCRP0_ADDR_ERR1 — Raw Status of Error from MPU_ADDR_INTR. Set irrespective if the Interupt is masked or unmasked in MPU_ADDR_INTR_ERRAGG_MASK (access R/W1TC)
  [10] MPU_ADDR_ERRAGG_R5SS0_CPU1_STATUS_RAW_MPU_OSPI_ADDR_ERR1 — Raw Status of Error from MPU_ADDR_INTR. Set irrespective if the Interupt is masked or unmasked in MPU_ADDR_INTR_ERRAGG_MASK (access R/W1TC)
  [9] MPU_ADDR_ERRAGG_R5SS0_CPU1_STATUS_RAW_MPU_MBOX_ADDR_ERR1 — Raw Status of Error from MPU_ADDR_INTR. Set irrespective if the Interupt is masked or unmasked in MPU_ADDR_INTR_ERRAGG_MASK (access R/W1TC)
  [8] MPU_ADDR_ERRAGG_R5SS0_CPU1_STATUS_RAW_MPU_DTHE_A_ADDR_ERR1 — Raw Status of Error from MPU_ADDR_INTR. Set irrespective if the Interupt is masked or unmasked in MPU_ADDR_INTR_ERRAGG_MASK (access R/W1TC)
  [5] MPU_ADDR_ERRAGG_R5SS0_CPU1_STATUS_RAW_MPU_CR5B0_AXIS_ADDR_ERR1 — Raw Status of Error from MPU_ADDR_INTR. Set irrespective if the Interupt is masked or unmasked in MPU_ADDR_INTR_ERRAGG_MASK (access R/W1TC)
  [4] MPU_ADDR_ERRAGG_R5SS0_CPU1_STATUS_RAW_MPU_CR5A0_AXIS_ADDR_ERR1 — Raw Status of Error from MPU_ADDR_INTR. Set irrespective if the Interupt is masked or unmasked in MPU_ADDR_INTR_ERRAGG_MASK (access R/W1TC)
  [2] MPU_ADDR_ERRAGG_R5SS0_CPU1_STATUS_RAW_MPU_L2_BANK_C_ADDR_ERR1 — Raw Status of Error from MPU_ADDR_INTR. Set irrespective if the Interupt is masked or unmasked in MPU_ADDR_INTR_ERRAGG_MASK (access R/W1TC)
  [1] MPU_ADDR_ERRAGG_R5SS0_CPU1_STATUS_RAW_MPU_L2_BANK_B_ADDR_ERR1 — Raw Status of Error from MPU_ADDR_INTR. Set irrespective if the Interupt is masked or unmasked in MPU_ADDR_INTR_ERRAGG_MASK (access R/W1TC)
  [0] MPU_ADDR_ERRAGG_R5SS0_CPU1_STATUS_RAW_MPU_L2_BANK_A_ADDR_ERR1 — Raw Status of Error from MPU_ADDR_INTR. Set irrespective if the Interupt is masked or unmasked in MPU_ADDR_INTR_ERRAGG_MASK (access R/W1TC)
0x8030 MSS_CTRL_MPU_PROT_ERRAGG_R5SS0_CORE1_MASK — This register Masks selected interrupt soures from generating MPU Protection Error Interrupt to R5SS0 CORE1 .
  [24] MPU_PROT_ERRAGG_R5SS0_CPU1_MASK_MPU_OSPI1_CFG_PROT_ERR1 — Mask Error from MPU_PROT_INTR to aggregated Error MPU_PROT_INTR_ERRAGG1 : Error is Masked0 : Error is Unmasked
  [23] MPU_PROT_ERRAGG_R5SS0_CPU1_MASK_MPU_OSPI1_PROT_ERR1 — Mask Error from MPU_PROT_INTR to aggregated Error MPU_PROT_INTR_ERRAGG1 : Error is Masked0 : Error is Unmasked
  [19] MPU_PROT_ERRAGG_R5SS0_CPU1_MASK_MPU_R5SS0_PROT_ERR1 — Mask Error from MPU_PROT_INTR to aggregated Error MPU_PROT_INTR_ERRAGG1 : Error is Masked0 : Error is Unmasked
  [18] MPU_PROT_ERRAGG_R5SS0_CPU1_MASK_MPU_OPTI_FLASH_PROT_ERR1 — Mask Error from MPU_PROT_INTR to aggregated Error MPU_PROT_INTR_ERRAGG1 : Error is Masked0 : Error is Unmasked
  [17] MPU_PROT_ERRAGG_R5SS0_CPU1_MASK_MPU_HSM_PROT_ERR1 — Mask Error from MPU_PROT_INTR to aggregated Error MPU_PROT_INTR_ERRAGG1 : Error is Masked0 : Error is Unmasked
  [14] MPU_PROT_ERRAGG_R5SS0_CPU1_MASK_MPU_CR5B0_AHB_PROT_ERR1 — Mask Error from MPU_PROT_INTR to aggregated Error MPU_PROT_INTR_ERRAGG1 : Error is Masked0 : Error is Unmasked
  [13] MPU_PROT_ERRAGG_R5SS0_CPU1_MASK_MPU_CR5A0_AHB_PROT_ERR1 — Mask Error from MPU_PROT_INTR to aggregated Error MPU_PROT_INTR_ERRAGG1 : Error is Masked0 : Error is Unmasked
  [12] MPU_PROT_ERRAGG_R5SS0_CPU1_MASK_MPU_SCRM2SCRP1_PROT_ERR1 — Mask Error from MPU_PROT_INTR to aggregated Error MPU_PROT_INTR_ERRAGG1 : Error is Masked0 : Error is Unmasked
  [11] MPU_PROT_ERRAGG_R5SS0_CPU1_MASK_MPU_SCRM2SCRP0_PROT_ERR1 — Mask Error from MPU_PROT_INTR to aggregated Error MPU_PROT_INTR_ERRAGG1 : Error is Masked0 : Error is Unmasked
  [10] MPU_PROT_ERRAGG_R5SS0_CPU1_MASK_MPU_OSPI_PROT_ERR1 — Mask Error from MPU_PROT_INTR to aggregated Error MPU_PROT_INTR_ERRAGG1 : Error is Masked0 : Error is Unmasked
  [9] MPU_PROT_ERRAGG_R5SS0_CPU1_MASK_MPU_MBOX_PROT_ERR1 — Mask Error from MPU_PROT_INTR to aggregated Error MPU_PROT_INTR_ERRAGG1 : Error is Masked0 : Error is Unmasked
  [8] MPU_PROT_ERRAGG_R5SS0_CPU1_MASK_MPU_DTHE_A_PROT_ERR1 — Mask Error from MPU_PROT_INTR to aggregated Error MPU_PROT_INTR_ERRAGG1 : Error is Masked0 : Error is Unmasked
  [5] MPU_PROT_ERRAGG_R5SS0_CPU1_MASK_MPU_CR5B0_AXIS_PROT_ERR1 — Mask Error from MPU_PROT_INTR to aggregated Error MPU_PROT_INTR_ERRAGG1 : Error is Masked0 : Error is Unmasked
  [4] MPU_PROT_ERRAGG_R5SS0_CPU1_MASK_MPU_CR5A0_AXIS_PROT_ERR1 — Mask Error from MPU_PROT_INTR to aggregated Error MPU_PROT_INTR_ERRAGG1 : Error is Masked0 : Error is Unmasked
  [2] MPU_PROT_ERRAGG_R5SS0_CPU1_MASK_MPU_L2_BANK_C_PROT_ERR1 — Mask Error from MPU_PROT_INTR to aggregated Error MPU_PROT_INTR_ERRAGG1 : Error is Masked0 : Error is Unmasked
  [1] MPU_PROT_ERRAGG_R5SS0_CPU1_MASK_MPU_L2_BANK_B_PROT_ERR1 — Mask Error from MPU_PROT_INTR to aggregated Error MPU_PROT_INTR_ERRAGG1 : Error is Masked0 : Error is Unmasked
  [0] MPU_PROT_ERRAGG_R5SS0_CPU1_MASK_MPU_L2_BANK_A_PROT_ERR1 — Mask Error from MPU_PROT_INTR to aggregated Error MPU_PROT_INTR_ERRAGG1 : Error is Masked0 : Error is Unmasked
0x8034 MSS_CTRL_MPU_PROT_ERRAGG_R5SS0_CORE1_STATUS access not given — This register shows the Status of Unmasked MPU Protection Errors to R5SS0 CORE1 .
  [24] MPU_PROT_ERRAGG_R5SS0_CPU1_STATUS_MPU_OSPI1_CFG_PROT_ERR1 — Status of Error from MPU_PROT_INTR. Set only if Interupt is unmasked in MPU_PROT_INTR_ERRAGG_MASKWrie 0x1 to clear this Error. (access R/W1TC)
  [23] MPU_PROT_ERRAGG_R5SS0_CPU1_STATUS_MPU_OSPI1_PROT_ERR1 — Status of Error from MPU_PROT_INTR. Set only if Interupt is unmasked in MPU_PROT_INTR_ERRAGG_MASKWrie 0x1 to clear this Error. (access R/W1TC)
  [19] MPU_PROT_ERRAGG_R5SS0_CPU1_STATUS_MPU_R5SS0_PROT_ERR1 — Status of Error from MPU_PROT_INTR. Set only if Interupt is unmasked in MPU_PROT_INTR_ERRAGG_MASKWrie 0x1 to clear this Error. (access R/W1TC)
  [18] MPU_PROT_ERRAGG_R5SS0_CPU1_STATUS_MPU_OPTI_FLASH_PROT_ERR1 — Status of Error from MPU_PROT_INTR. Set only if Interupt is unmasked in MPU_PROT_INTR_ERRAGG_MASKWrie 0x1 to clear this Error. (access R/W1TC)
  [17] MPU_PROT_ERRAGG_R5SS0_CPU1_STATUS_MPU_HSM_PROT_ERR1 — Status of Error from MPU_PROT_INTR. Set only if Interupt is unmasked in MPU_PROT_INTR_ERRAGG_MASKWrie 0x1 to clear this Error. (access R/W1TC)
  [14] MPU_PROT_ERRAGG_R5SS0_CPU1_STATUS_MPU_CR5B0_AHB_PROT_ERR1 — Status of Error from MPU_PROT_INTR. Set only if Interupt is unmasked in MPU_PROT_INTR_ERRAGG_MASKWrie 0x1 to clear this Error. (access R/W1TC)
  [13] MPU_PROT_ERRAGG_R5SS0_CPU1_STATUS_MPU_CR5A0_AHB_PROT_ERR1 — Status of Error from MPU_PROT_INTR. Set only if Interupt is unmasked in MPU_PROT_INTR_ERRAGG_MASKWrie 0x1 to clear this Error. (access R/W1TC)
  [12] MPU_PROT_ERRAGG_R5SS0_CPU1_STATUS_MPU_SCRM2SCRP1_PROT_ERR1 — Status of Error from MPU_PROT_INTR. Set only if Interupt is unmasked in MPU_PROT_INTR_ERRAGG_MASKWrie 0x1 to clear this Error. (access R/W1TC)
  [11] MPU_PROT_ERRAGG_R5SS0_CPU1_STATUS_MPU_SCRM2SCRP0_PROT_ERR1 — Status of Error from MPU_PROT_INTR. Set only if Interupt is unmasked in MPU_PROT_INTR_ERRAGG_MASKWrie 0x1 to clear this Error. (access R/W1TC)
  [10] MPU_PROT_ERRAGG_R5SS0_CPU1_STATUS_MPU_OSPI_PROT_ERR1 — Status of Error from MPU_PROT_INTR. Set only if Interupt is unmasked in MPU_PROT_INTR_ERRAGG_MASKWrie 0x1 to clear this Error. (access R/W1TC)
  [9] MPU_PROT_ERRAGG_R5SS0_CPU1_STATUS_MPU_MBOX_PROT_ERR1 — Status of Error from MPU_PROT_INTR. Set only if Interupt is unmasked in MPU_PROT_INTR_ERRAGG_MASKWrie 0x1 to clear this Error. (access R/W1TC)
  [8] MPU_PROT_ERRAGG_R5SS0_CPU1_STATUS_MPU_DTHE_A_PROT_ERR1 — Status of Error from MPU_PROT_INTR. Set only if Interupt is unmasked in MPU_PROT_INTR_ERRAGG_MASKWrie 0x1 to clear this Error. (access R/W1TC)
  [5] MPU_PROT_ERRAGG_R5SS0_CPU1_STATUS_MPU_CR5B0_AXIS_PROT_ERR1 — Status of Error from MPU_PROT_INTR. Set only if Interupt is unmasked in MPU_PROT_INTR_ERRAGG_MASKWrie 0x1 to clear this Error. (access R/W1TC)
  [4] MPU_PROT_ERRAGG_R5SS0_CPU1_STATUS_MPU_CR5A0_AXIS_PROT_ERR1 — Status of Error from MPU_PROT_INTR. Set only if Interupt is unmasked in MPU_PROT_INTR_ERRAGG_MASKWrie 0x1 to clear this Error. (access R/W1TC)
  [2] MPU_PROT_ERRAGG_R5SS0_CPU1_STATUS_MPU_L2_BANK_C_PROT_ERR1 — Status of Error from MPU_PROT_INTR. Set only if Interupt is unmasked in MPU_PROT_INTR_ERRAGG_MASKWrie 0x1 to clear this Error. (access R/W1TC)
  [1] MPU_PROT_ERRAGG_R5SS0_CPU1_STATUS_MPU_L2_BANK_B_PROT_ERR1 — Status of Error from MPU_PROT_INTR. Set only if Interupt is unmasked in MPU_PROT_INTR_ERRAGG_MASKWrie 0x1 to clear this Error. (access R/W1TC)
  [0] MPU_PROT_ERRAGG_R5SS0_CPU1_STATUS_MPU_L2_BANK_A_PROT_ERR1 — Status of Error from MPU_PROT_INTR. Set only if Interupt is unmasked in MPU_PROT_INTR_ERRAGG_MASKWrie 0x1 to clear this Error. (access R/W1TC)
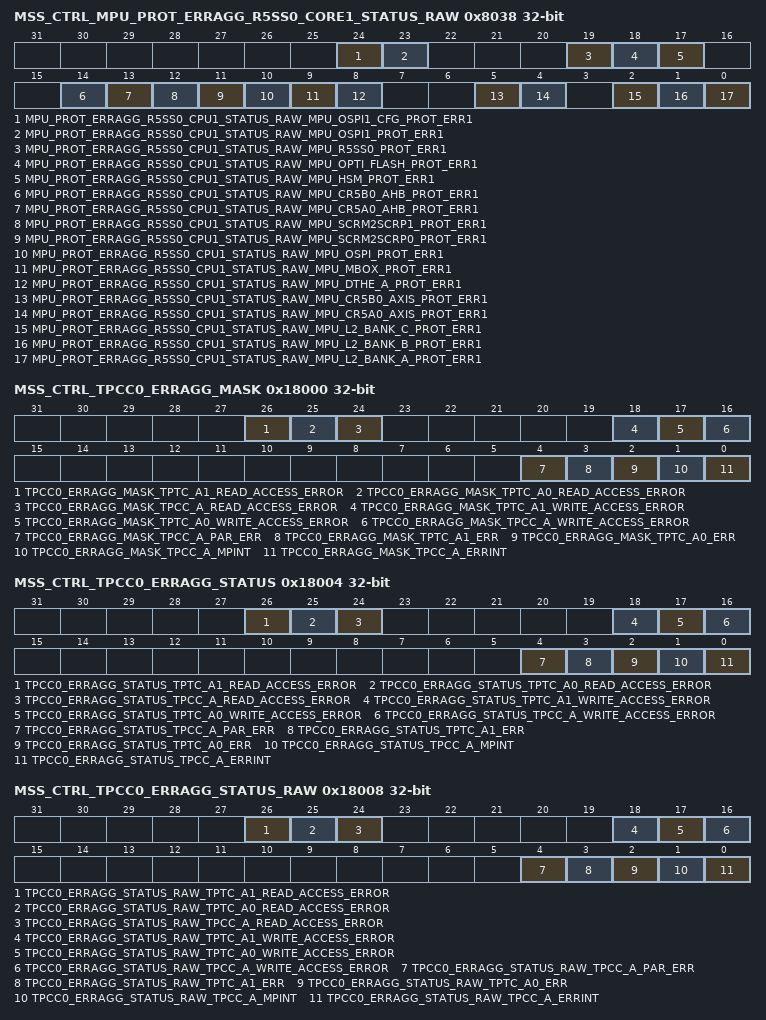
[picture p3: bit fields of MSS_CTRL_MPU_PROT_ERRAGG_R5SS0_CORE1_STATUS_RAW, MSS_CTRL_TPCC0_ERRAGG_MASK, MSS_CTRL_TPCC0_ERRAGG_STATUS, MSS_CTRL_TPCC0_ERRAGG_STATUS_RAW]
0x8038 MSS_CTRL_MPU_PROT_ERRAGG_R5SS0_CORE1_STATUS_RAW access not given — This register shows the Status of all MPU Protection Errors.
  [24] MPU_PROT_ERRAGG_R5SS0_CPU1_STATUS_RAW_MPU_OSPI1_CFG_PROT_ERR1 — Raw Status of Error from MPU_PROT_INTR. Set irrespective if the Interupt is masked or unmasked in MPU_PROT_INTR_ERRAGG_MASK (access R/W1TC)
  [23] MPU_PROT_ERRAGG_R5SS0_CPU1_STATUS_RAW_MPU_OSPI1_PROT_ERR1 — Raw Status of Error from MPU_PROT_INTR. Set irrespective if the Interupt is masked or unmasked in MPU_PROT_INTR_ERRAGG_MASK (access R/W1TC)
  [19] MPU_PROT_ERRAGG_R5SS0_CPU1_STATUS_RAW_MPU_R5SS0_PROT_ERR1 — Raw Status of Error from MPU_PROT_INTR. Set irrespective if the Interupt is masked or unmasked in MPU_PROT_INTR_ERRAGG_MASK (access R/W1TC)
  [18] MPU_PROT_ERRAGG_R5SS0_CPU1_STATUS_RAW_MPU_OPTI_FLASH_PROT_ERR1 — Raw Status of Error from MPU_PROT_INTR. Set irrespective if the Interupt is masked or unmasked in MPU_PROT_INTR_ERRAGG_MASK (access R/W1TC)
  [17] MPU_PROT_ERRAGG_R5SS0_CPU1_STATUS_RAW_MPU_HSM_PROT_ERR1 — Raw Status of Error from MPU_PROT_INTR. Set irrespective if the Interupt is masked or unmasked in MPU_PROT_INTR_ERRAGG_MASK (access R/W1TC)
  [14] MPU_PROT_ERRAGG_R5SS0_CPU1_STATUS_RAW_MPU_CR5B0_AHB_PROT_ERR1 — Raw Status of Error from MPU_PROT_INTR. Set irrespective if the Interupt is masked or unmasked in MPU_PROT_INTR_ERRAGG_MASK (access R/W1TC)
  [13] MPU_PROT_ERRAGG_R5SS0_CPU1_STATUS_RAW_MPU_CR5A0_AHB_PROT_ERR1 — Raw Status of Error from MPU_PROT_INTR. Set irrespective if the Interupt is masked or unmasked in MPU_PROT_INTR_ERRAGG_MASK (access R/W1TC)
  [12] MPU_PROT_ERRAGG_R5SS0_CPU1_STATUS_RAW_MPU_SCRM2SCRP1_PROT_ERR1 — Raw Status of Error from MPU_PROT_INTR. Set irrespective if the Interupt is masked or unmasked in MPU_PROT_INTR_ERRAGG_MASK (access R/W1TC)
  [11] MPU_PROT_ERRAGG_R5SS0_CPU1_STATUS_RAW_MPU_SCRM2SCRP0_PROT_ERR1 — Raw Status of Error from MPU_PROT_INTR. Set irrespective if the Interupt is masked or unmasked in MPU_PROT_INTR_ERRAGG_MASK (access R/W1TC)
  [10] MPU_PROT_ERRAGG_R5SS0_CPU1_STATUS_RAW_MPU_OSPI_PROT_ERR1 — Raw Status of Error from MPU_PROT_INTR. Set irrespective if the Interupt is masked or unmasked in MPU_PROT_INTR_ERRAGG_MASK (access R/W1TC)
  [9] MPU_PROT_ERRAGG_R5SS0_CPU1_STATUS_RAW_MPU_MBOX_PROT_ERR1 — Raw Status of Error from MPU_PROT_INTR. Set irrespective if the Interupt is masked or unmasked in MPU_PROT_INTR_ERRAGG_MASK (access R/W1TC)
  [8] MPU_PROT_ERRAGG_R5SS0_CPU1_STATUS_RAW_MPU_DTHE_A_PROT_ERR1 — Raw Status of Error from MPU_PROT_INTR. Set irrespective if the Interupt is masked or unmasked in MPU_PROT_INTR_ERRAGG_MASK (access R/W1TC)
  [5] MPU_PROT_ERRAGG_R5SS0_CPU1_STATUS_RAW_MPU_CR5B0_AXIS_PROT_ERR1 — Raw Status of Error from MPU_PROT_INTR. Set irrespective if the Interupt is masked or unmasked in MPU_PROT_INTR_ERRAGG_MASK (access R/W1TC)
  [4] MPU_PROT_ERRAGG_R5SS0_CPU1_STATUS_RAW_MPU_CR5A0_AXIS_PROT_ERR1 — Raw Status of Error from MPU_PROT_INTR. Set irrespective if the Interupt is masked or unmasked in MPU_PROT_INTR_ERRAGG_MASK (access R/W1TC)
  [2] MPU_PROT_ERRAGG_R5SS0_CPU1_STATUS_RAW_MPU_L2_BANK_C_PROT_ERR1 — Raw Status of Error from MPU_PROT_INTR. Set irrespective if the Interupt is masked or unmasked in MPU_PROT_INTR_ERRAGG_MASK (access R/W1TC)
  [1] MPU_PROT_ERRAGG_R5SS0_CPU1_STATUS_RAW_MPU_L2_BANK_B_PROT_ERR1 — Raw Status of Error from MPU_PROT_INTR. Set irrespective if the Interupt is masked or unmasked in MPU_PROT_INTR_ERRAGG_MASK (access R/W1TC)
  [0] MPU_PROT_ERRAGG_R5SS0_CPU1_STATUS_RAW_MPU_L2_BANK_A_PROT_ERR1 — Raw Status of Error from MPU_PROT_INTR. Set irrespective if the Interupt is masked or unmasked in MPU_PROT_INTR_ERRAGG_MASK (access R/W1TC)
0x18000 MSS_CTRL_TPCC0_ERRAGG_MASK — This register Masks selected interrupt soures from generating the Aggregated TPCC0 Error Interrupt.
  [26] TPCC0_ERRAGG_MASK_TPTC_A1_READ_ACCESS_ERROR — Mask Error from MSS_TPTC_A1 to aggregated Error MSS_TPCC_A_ERRAGG1'b1 Error is Masked1'b0 Error is Unmasked
  [25] TPCC0_ERRAGG_MASK_TPTC_A0_READ_ACCESS_ERROR — Mask Error from MSS_TPTC_A0 to aggregated Error MSS_TPCC_A_ERRAGG1'b1 Error is Masked1'b0 Error is Unmasked
  [24] TPCC0_ERRAGG_MASK_TPCC_A_READ_ACCESS_ERROR — Mask Error from MSS_TPCC_A to aggregated Error MSS_TPCC_A_ERRAGG1'b1 Error is Masked1'b0 Error is Unmasked
  [18] TPCC0_ERRAGG_MASK_TPTC_A1_WRITE_ACCESS_ERROR — Mask Error from MSS_TPTC_A1 to aggregated Error MSS_TPCC_A_ERRAGG1'b1 Error is Masked1'b0 Error is Unmasked
  [17] TPCC0_ERRAGG_MASK_TPTC_A0_WRITE_ACCESS_ERROR — Mask Error from MSS_TPTC_A0 to aggregated Error MSS_TPCC_A_ERRAGG1'b1 Error is Masked1'b0 Error is Unmasked
  [16] TPCC0_ERRAGG_MASK_TPCC_A_WRITE_ACCESS_ERROR — Mask Error from MSS_TPCC_A to aggregated Error MSS_TPCC_A_ERRAGG1'b1 Error is Masked1'b0 Error is Unmasked
  [4] TPCC0_ERRAGG_MASK_TPCC_A_PAR_ERR — Mask Error from MSS_TPCC_A to aggregated Error MSS_TPCC_A_ERRAGG1'b1 Error is Masked1'b0 Error is Unmasked
  [3] TPCC0_ERRAGG_MASK_TPTC_A1_ERR — Mask Error from MSS_TPTC_A1 to aggregated Error MSS_TPCC_A_ERRAGG1'b1 Error is Masked1'b0 Error is Unmasked
  [2] TPCC0_ERRAGG_MASK_TPTC_A0_ERR — Mask Error from MSS_TPTC_A0 to aggregated Error MSS_TPCC_A_ERRAGG1'b1 Error is Masked1'b0 Error is Unmasked
  [1] TPCC0_ERRAGG_MASK_TPCC_A_MPINT — Mask Error from MSS_TPCC_A to aggregated Error MSS_TPCC_A_ERRAGG1'b1 Error is Masked1'b0 Error is Unmasked
  [0] TPCC0_ERRAGG_MASK_TPCC_A_ERRINT — Mask Error from MSS_TPCC_A to aggregated Error MSS_TPCC_A_ERRAGG1'b1 Error is Masked1'b0 Error is Unmasked
0x18004 MSS_CTRL_TPCC0_ERRAGG_STATUS access not given — This register shows the Status of Unmasked Errors from TPCC0.
  [26] TPCC0_ERRAGG_STATUS_TPTC_A1_READ_ACCESS_ERROR — Status of Error from MSS_TPTC_A1. Set only if Interupt is unmasked in TPCC0_ERRAGG_MASKWrie 0x1 to clear this Error. (access R/W1TC)
  [25] TPCC0_ERRAGG_STATUS_TPTC_A0_READ_ACCESS_ERROR — Status of Error from MSS_TPTC_A0. Set only if Interupt is unmasked in TPCC0_ERRAGG_MASKWrie 0x1 to clear this Error. (access R/W1TC)
  [24] TPCC0_ERRAGG_STATUS_TPCC_A_READ_ACCESS_ERROR — Status of Error from MSS_TPCC_A. Set only if Interupt is unmasked in TPCC0_ERRAGG_MASKWrie 0x1 to clear this Error. (access R/W1TC)
  [18] TPCC0_ERRAGG_STATUS_TPTC_A1_WRITE_ACCESS_ERROR — Status of Error from MSS_TPTC_A1. Set only if Interupt is unmasked in TPCC0_ERRAGG_MASKWrie 0x1 to clear this Error. (access R/W1TC)
  [17] TPCC0_ERRAGG_STATUS_TPTC_A0_WRITE_ACCESS_ERROR — Status of Error from MSS_TPTC_A0. Set only if Interupt is unmasked in TPCC0_ERRAGG_MASKWrie 0x1 to clear this Error. (access R/W1TC)
  [16] TPCC0_ERRAGG_STATUS_TPCC_A_WRITE_ACCESS_ERROR — Status of Error from MSS_TPCC_A. Set only if Interupt is unmasked in TPCC0_ERRAGG_MASKWrie 0x1 to clear this Error. (access R/W1TC)
  [4] TPCC0_ERRAGG_STATUS_TPCC_A_PAR_ERR — Status of Error from MSS_TPCC_A. Set only if Interupt is unmasked in TPCC0_ERRAGG_MASKWrie 0x1 to clear this Error. (access R/W1TC)
  [3] TPCC0_ERRAGG_STATUS_TPTC_A1_ERR — Status of Error from MSS_TPTC_A1. Set only if Interupt is unmasked in TPCC0_ERRAGG_MASKWrie 0x1 to clear this Error. (access R/W1TC)
  [2] TPCC0_ERRAGG_STATUS_TPTC_A0_ERR — Status of Error from MSS_TPTC_A0. Set only if Interupt is unmasked in TPCC0_ERRAGG_MASKWrie 0x1 to clear this Error. (access R/W1TC)
  [1] TPCC0_ERRAGG_STATUS_TPCC_A_MPINT — Status of Error from MSS_TPCC_A. Set only if Interupt is unmasked in TPCC0_ERRAGG_MASKWrie 0x1 to clear this Error. (access R/W1TC)
  [0] TPCC0_ERRAGG_STATUS_TPCC_A_ERRINT — Status of Error from MSS_TPCC_A. Set only if Interupt is unmasked in TPCC0_ERRAGG_MASKWrie 0x1 to clear this Error. (access R/W1TC)
0x18008 MSS_CTRL_TPCC0_ERRAGG_STATUS_RAW access not given — This register shows the Status of all Errors from TPCC0.
  [26] TPCC0_ERRAGG_STATUS_RAW_TPTC_A1_READ_ACCESS_ERROR — Raw Status of Error from MSS_TPTC_A1. Set irrespective if the Interupt is masked or unmasked in TPCC0_ERRAGG_MASK (access R/W1TC)
  [25] TPCC0_ERRAGG_STATUS_RAW_TPTC_A0_READ_ACCESS_ERROR — Raw Status of Error from MSS_TPTC_A0. Set irrespective if the Interupt is masked or unmasked in TPCC0_ERRAGG_MASK (access R/W1TC)
  [24] TPCC0_ERRAGG_STATUS_RAW_TPCC_A_READ_ACCESS_ERROR — Raw Status of Error from MSS_TPCC_A. Set irrespective if the Interupt is masked or unmasked in TPCC0_ERRAGG_MASK (access R/W1TC)
  [18] TPCC0_ERRAGG_STATUS_RAW_TPTC_A1_WRITE_ACCESS_ERROR — Raw Status of Error from MSS_TPTC_A1. Set irrespective if the Interupt is masked or unmasked in TPCC0_ERRAGG_MASK (access R/W1TC)
  [17] TPCC0_ERRAGG_STATUS_RAW_TPTC_A0_WRITE_ACCESS_ERROR — Raw Status of Error from MSS_TPTC_A0. Set irrespective if the Interupt is masked or unmasked in TPCC0_ERRAGG_MASK (access R/W1TC)
  [16] TPCC0_ERRAGG_STATUS_RAW_TPCC_A_WRITE_ACCESS_ERROR — Raw Status of Error from MSS_TPCC_A. Set irrespective if the Interupt is masked or unmasked in TPCC0_ERRAGG_MASK (access R/W1TC)
  [4] TPCC0_ERRAGG_STATUS_RAW_TPCC_A_PAR_ERR — Raw Status of Error from MSS_TPCC_A. Set irrespective if the Interupt is masked or unmasked in TPCC0_ERRAGG_MASK (access R/W1TC)
  [3] TPCC0_ERRAGG_STATUS_RAW_TPTC_A1_ERR — Raw Status of Error from MSS_TPTC_A1. Set irrespective if the Interupt is masked or unmasked in TPCC0_ERRAGG_MASK (access R/W1TC)
  [2] TPCC0_ERRAGG_STATUS_RAW_TPTC_A0_ERR — Raw Status of Error from MSS_TPTC_A0. Set irrespective if the Interupt is masked or unmasked in TPCC0_ERRAGG_MASK (access R/W1TC)
  [1] TPCC0_ERRAGG_STATUS_RAW_TPCC_A_MPINT — Raw Status of Error from MSS_TPCC_A. Set irrespective if the Interupt is masked or unmasked in TPCC0_ERRAGG_MASK (access R/W1TC)
  [0] TPCC0_ERRAGG_STATUS_RAW_TPCC_A_ERRINT — Raw Status of Error from MSS_TPCC_A. Set irrespective if the Interupt is masked or unmasked in TPCC0_ERRAGG_MASK (access R/W1TC)
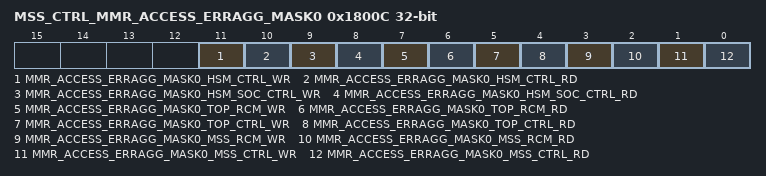
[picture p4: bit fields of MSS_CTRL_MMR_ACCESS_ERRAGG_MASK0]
0x1800C MSS_CTRL_MMR_ACCESS_ERRAGG_MASK0 — This register Masks selected interrupt soures from generating the Aggregated MMR Access Error Interrupt.
  [11] MMR_ACCESS_ERRAGG_MASK0_HSM_CTRL_WR — Mask Interrupt from HSM_CTRL to aggregated Interrupt MSS_PERIPH_ACCESS_ERRAGG1 : Interrupt is Masked0 : Interrupt is Unmasked
  [10] MMR_ACCESS_ERRAGG_MASK0_HSM_CTRL_RD — Mask Interrupt from HSM_CTRL to aggregated Interrupt MSS_PERIPH_ACCESS_ERRAGG1 : Interrupt is Masked0 : Interrupt is Unmasked
  [9] MMR_ACCESS_ERRAGG_MASK0_HSM_SOC_CTRL_WR — Mask Interrupt from HSM_SOC_CTRL to aggregated Interrupt MSS_PERIPH_ACCESS_ERRAGG1 : Interrupt is Masked0 : Interrupt is Unmasked
  [8] MMR_ACCESS_ERRAGG_MASK0_HSM_SOC_CTRL_RD — Mask Interrupt from HSM_SOC_CTRL to aggregated Interrupt MSS_PERIPH_ACCESS_ERRAGG1 : Interrupt is Masked0 : Interrupt is Unmasked
  [7] MMR_ACCESS_ERRAGG_MASK0_TOP_RCM_WR — Mask Interrupt from TOP_RCM to aggregated Interrupt MSS_PERIPH_ACCESS_ERRAGG1 : Interrupt is Masked0 : Interrupt is Unmasked
  [6] MMR_ACCESS_ERRAGG_MASK0_TOP_RCM_RD — Mask Interrupt from TOP_RCM to aggregated Interrupt MSS_PERIPH_ACCESS_ERRAGG1 : Interrupt is Masked0 : Interrupt is Unmasked
  [5] MMR_ACCESS_ERRAGG_MASK0_TOP_CTRL_WR — Mask Interrupt from TOP_CTRL to aggregated Interrupt MSS_PERIPH_ACCESS_ERRAGG1 : Interrupt is Masked0 : Interrupt is Unmasked
  [4] MMR_ACCESS_ERRAGG_MASK0_TOP_CTRL_RD — Mask Interrupt from TOP_CTRL to aggregated Interrupt MSS_PERIPH_ACCESS_ERRAGG1 : Interrupt is Masked0 : Interrupt is Unmasked
  [3] MMR_ACCESS_ERRAGG_MASK0_MSS_RCM_WR — Mask Interrupt from MSS_RCM to aggregated Interrupt MSS_PERIPH_ACCESS_ERRAGG1 : Interrupt is Masked0 : Interrupt is Unmasked
  [2] MMR_ACCESS_ERRAGG_MASK0_MSS_RCM_RD — Mask Interrupt from MSS_RCM to aggregated Interrupt MSS_PERIPH_ACCESS_ERRAGG1 : Interrupt is Masked0 : Interrupt is Unmasked
  [1] MMR_ACCESS_ERRAGG_MASK0_MSS_CTRL_WR — Mask Interrupt from MSS_CTRL to aggregated Interrupt MSS_PERIPH_ACCESS_ERRAGG1 : Interrupt is Masked0 : Interrupt is Unmasked
  [0] MMR_ACCESS_ERRAGG_MASK0_MSS_CTRL_RD — Mask Interrupt from MSS_CTRL to aggregated Interrupt MSS_PERIPH_ACCESS_ERRAGG1 : Interrupt is Masked0 : Interrupt is Unmasked
